AUTOSAR XML (schema 00044)
package /E40_Platform_System_SystemPackage/Components
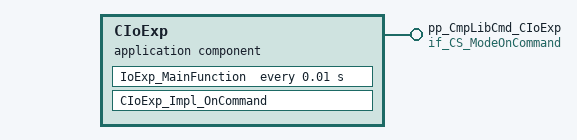
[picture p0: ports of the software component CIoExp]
  application sw component type CIoExp
    provide port pp_CmpLibCmd_CIoExp: server-com-spec{operation=Impl_OnCommand, queue-length=1}, provided-interface=if_CS_ModeOnCommand
    behavior IB_CIoExp: port-api-option{enable-take-address=false, indirect-api=false, port=pp_CmpLibCmd_CIoExp}
      operation invoked event OIE_pp_CmpLibCmd_CIoExp_CIoExp_Impl_OnCommandTrigByImpl_OnCommand: start-on-event=CIoExp_Impl_OnCommand, operation=pp_CmpLibCmd_CIoExp.Impl_OnCommand
      timing event TEIoExp_MainFunction: start-on-event=IoExp_MainFunction, period=0.01
      runnable CIoExp_Impl_OnCommand: can-be-invoked-concurrently=true
      runnable IoExp_MainFunction: can-be-invoked-concurrently=true
  swc implementation IMPL_CIoExp: behavior=IB_CIoExp
